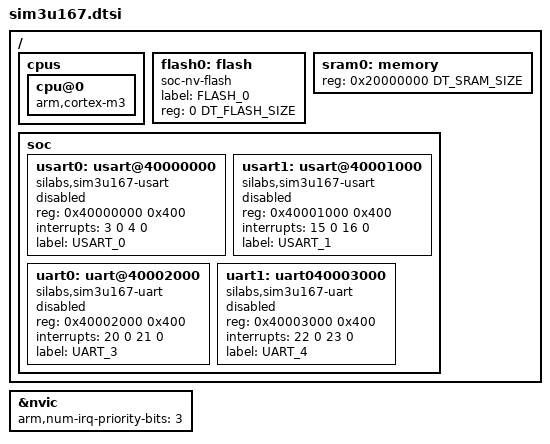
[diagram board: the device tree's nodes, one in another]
#include <arm/armv7-m.dtsi>
#include <silabs/mem.h>

/ {
	cpus {
		cpu@0 {
			compatible = "arm,cortex-m3";
		};
	};

	flash0: flash {
		compatible = "soc-nv-flash";
		label = "FLASH_0";
		reg = <0 DT_FLASH_SIZE>;
	};

	sram0: memory {
		reg = <0x20000000 DT_SRAM_SIZE>;
	};

	soc {
		usart0: usart@40000000 { /* USART0 */
			compatible = "silabs,sim3u167-usart";
			reg = <0x40000000 0x400>;
			interrupts = <3 0 4 0>;
			status = "disabled";
			label = "USART_0";
		};

		usart1: usart@40001000 { /* USART1 */
			compatible = "silabs,sim3u167-usart";
			reg = <0x40001000 0x400>;
			interrupts = <15 0 16 0>;
			status = "disabled";
			label = "USART_1";
		};

		uart0: uart@40002000 { /* UART0 */
			compatible = "silabs,sim3u167-uart";
			reg = <0x40002000 0x400>;
			interrupts = <20 0 21 0>;
			status = "disabled";
			label = "UART_3";
		};

		uart1: uart040003000 { /* UART1 */
			compatible = "silabs,sim3u167-uart";
			reg = <0x40003000 0x400>;
			interrupts = <22 0 23 0>;
			status = "disabled";
			label = "UART_4";
		};
	};
};

&nvic {
	arm,num-irq-priority-bits = <3>;
};
